# PY32F002Cxx register map
Vendor: Puya; Series: PY32F0; File version: 1.0.0
CPU: CM0+ r0p1, little endian, no MPU, no FPU, 4 interrupt priority bits
Registers are 32-bit, read-write, reset 0x0 unless marked. A register's access mark holds for its fields unless they carry their own. Offsets are from the block's base; [hi:lo] are bit positions.

## TIM13
Base 0x40002400
Same registers: TIM14 0x40002000
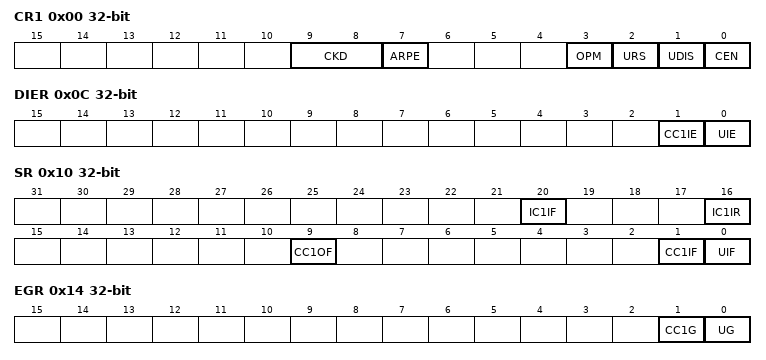
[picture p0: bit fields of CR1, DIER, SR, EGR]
0x00 CR1
  [9:8] CKD, [7] ARPE, [3] OPM, [2] URS, [1] UDIS, [0] CEN
0x0C DIER
  [1] CC1IE, [0] UIE
0x10 SR
  [20] IC1IF, [16] IC1IR, [9] CC1OF, [1] CC1IF, [0] UIF
0x14 EGR
  [1] CC1G — Capture/Compare 1 Generation
  [0] UG
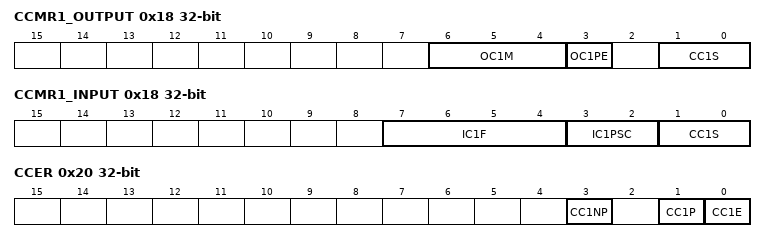
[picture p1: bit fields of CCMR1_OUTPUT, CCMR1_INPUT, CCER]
0x18 CCMR1_OUTPUT
  [6:4] OC1M, [3] OC1PE, [1:0] CC1S
0x18 CCMR1_INPUT (alternate view of CCMR1_OUTPUT)
  [7:4] IC1F, [3:2] IC1PSC, [1:0] CC1S
0x20 CCER
  [3] CC1NP, [1] CC1P, [0] CC1E
0x24 CNT
  [15:0] CNT
0x28 PSC
  [15:0] PSC
0x2C ARR
  [15:0] ARR
0x34 CCR1
  [15:0] CCR1
0x5C TISEL
  [3:0] TI1SEL

## UART
Base 0x40004800
0x00 DR
  [8:0] DR — Receive/send data register
0x04 BRR
  [15:0] BRR — Baud rate register
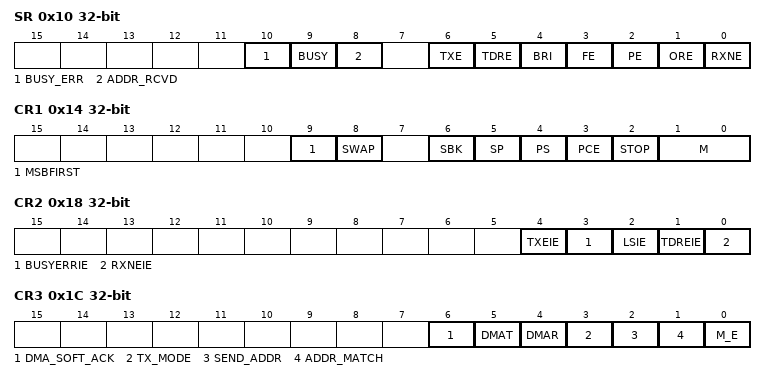
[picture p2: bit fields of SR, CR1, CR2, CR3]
0x10 SR
  [10] BUSY_ERR — Busy Detect Error
  [9] BUSY ro — UART Busy
  [8] ADDR_RCVD — Address Received Bit
  [6] TXE ro — Transmitter Empty bit
  [5] TDRE ro — Transmit Holding Register Empty bit
  [4] BRI — Break Interrupt bit
  [3] FE — Framing Error bit
  [2] PE — Parity Error bit
  [1] ORE — Overrun error bit
  [0] RXNE ro — Receive register not empty
0x14 CR1
  [9] MSBFIRST — MSB first mode
  [8] SWAP — TX/RX pin swap
  [6] SBK — Send Break
  [5] SP — Stick Parity
  [4] PS — Even Parity Select
  [3] PCE — Parity Enable
  [2] STOP — Number of stop bits
  [1:0] M — Data Length Select
0x18 CR2
  [4] TXEIE — Enable TX state interruption
  [3] BUSYERRIE — Enable Busyerr state interruption
  [2] LSIE — Enable Receiver Line Status Interrupt
  [1] TDREIE — Enable Transmit Holding Register Empty Interrupt
  [0] RXNEIE — Enable Received Data Available Interrupt
0x1C CR3
  [6] DMA_SOFT_ACK — DMA software ack
  [5] DMAT — DMA transmit enable
  [4] DMAR — DMA receive enable
  [3] TX_MODE — Transmit mode control bit
  [2] SEND_ADDR — Send address control bit
  [1] ADDR_MATCH — Address Match Mode
  [0] M_E — Extension for DLS
0x20 RAR
  [7:0] RAR — Receive address matching register
0x24 TAR
  [7:0] TAR — Transmit address matching register
0x28 BRRF
  [3:0] BRRF — Baud rate fractional register

## USART1 — Universal synchronous asynchronous receiver transmitter
Base 0x40013800
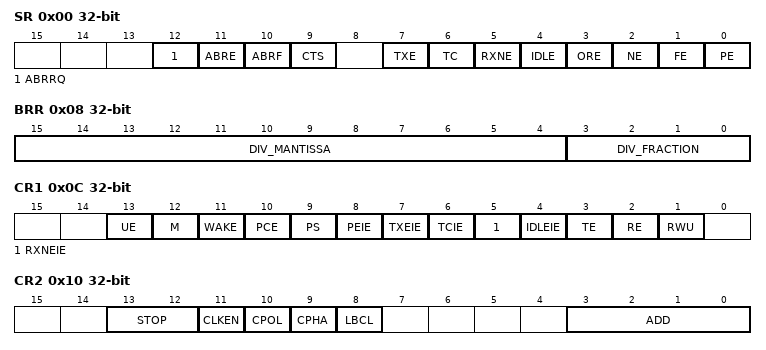
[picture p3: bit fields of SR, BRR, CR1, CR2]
0x00 SR — Status register
  [12] ABRRQ — Automate baudrate detection requeset
  [11] ABRE ro — Automate baudrate detection error flag
  [10] ABRF ro — Automate baudrate detection flag
  [9] CTS — CTS flag
  [7] TXE ro — Transmit data register empty
  [6] TC — Transmission complete
  [5] RXNE — Read data register not empty
  [4] IDLE ro — IDLE line detected
  [3] ORE ro — Overrun error
  [2] NE ro — Noise error flag
  [1] FE ro — Framing error
  [0] PE ro — Parity error
0x04 DR — Data register
  [8:0] DR — Data value
0x08 BRR — Baud rate register
  [15:4] DIV_MANTISSA — mantissa of USARTDIV
  [3:0] DIV_FRACTION — fraction of USARTDIV
0x0C CR1 — Control register 1
  [13] UE — USART enable
  [12] M — Word length
  [11] WAKE — Wakeup method
  [10] PCE — Parity control enable
  [9] PS — Parity selection
  [8] PEIE — PE interrupt enable
  [7] TXEIE — TXE interrupt enable
  [6] TCIE — Transmission complete interrupt enable
  [5] RXNEIE — RXNE interrupt enable
  [4] IDLEIE — IDLE interrupt enable
  [3] TE — Transmitter enable
  [2] RE — Receiver enable
  [1] RWU — Receiver wakeup
0x10 CR2 — Control register 2
  [13:12] STOP — STOP bits
  [11] CLKEN — Clock enable
  [10] CPOL — Clock polarity
  [9] CPHA — Clock phase
  [8] LBCL — Last bit clock pulse
  [3:0] ADD — Address of the USART node
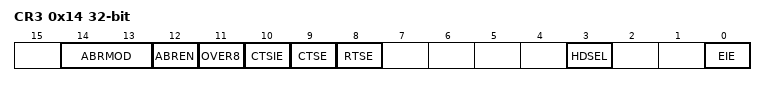
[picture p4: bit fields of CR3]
0x14 CR3 — Control register 3
  [14:13] ABRMOD — Auto baudrate mode
  [12] ABREN — Auto baudrate enable
  [11] OVER8 — Oversampling mode
  [10] CTSIE — CTS interrupt enable
  [9] CTSE — CTS enable
  [8] RTSE — RTS enable
  [3] HDSEL — Half-duplex selection
  [0] EIE — Error interrupt enable

## VREF
Base 0x40010100
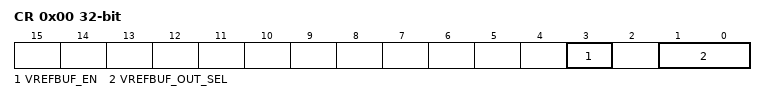
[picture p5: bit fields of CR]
0x00 CR
  [3] VREFBUF_EN, [1:0] VREFBUF_OUT_SEL
